# GD32E25x register map
File version: 1.0
GD32E25x ARM 32-bit Cortex-M23 Microcontroller based device
CPU: CM23 r1p0, little endian, no MPU, no FPU, 2 interrupt priority bits
Registers are 32-bit, read-write, reset 0x0 unless marked. A register's access mark holds for its fields unless they carry their own. Offsets are from the block's base; lines under a group give offsets from that group; [hi:lo] are bit positions; {n}, {i} and the like mark numbered series; 'fields as' and 'values as' point back to an identical list; <NAME> marks a mode.

## Memory map
0x40000000 TIMER1 size 0x400 — General-level0-timer
0x40000400 TIMER2 size 0x400 — General-purpose-timers
0x40001000 TIMER5 size 0x400 — Basic-timers
0x40001400 TIMER6 size 0x400 — Basic-timers
0x40002000 TIMER13 size 0x400 — General-purpose-timers
0x40002800 RTC size 0x400 — Real-time clock
0x40002C00 WWDGT size 0x400 — Window watchdog timer
0x40003000 FWDGT size 0x400 — free watchdog timer
0x40003800 SPI1 size 0x400 — Serial Peripheral Interface 1
0x40004400 USART1 size 0x400
0x40005400 I2C0 size 0x400 — Inter integrated circuit
0x40005800 I2C1 size 0x400
0x40007000 PMU size 0x400 — Power management unit
0x40007400 DAC0 size 0x400 — Digital-to-analog converter
0x4000C000 I2C2 size 0x400 — Inter integrated circuit
0x4000CC00 DAC1 size 0x400
0x40010000 SYSCFG size 0x400 — System configuration controller
0x4001001C CMP size 0x80 — Comparator
0x40010400 EXTI size 0x400 — External interrupt/event controller
0x40012400 ADC size 0x400 — Analog to digital converter
0x40012C00 TIMER0 size 0x400 — Advanced-timers
0x40013000 SPI0 size 0x400 — Serial peripheral interface
0x40013800 USART0 size 0x400 — Universal synchronous asynchronous receiver transmitter
0x40014000 TIMER14 size 0x400 — General-purpose-timers
0x40014400 TIMER15 size 0x400 — General-purpose-timers
0x40014800 TIMER16 size 0x400
0x40015800 DBG size 0x400 — Debug
0x40020000 DMA size 0x400 — DMA controller
0x40021000 RCU size 0x400 — Reset and clock unit
0x40022000 FMC size 0x400
0x40023000 CRC size 0x400 — cyclic redundancy check calculation unit
0x40038000 CLA size 0x400 — Configurable Logic Array unit
0x48000000 GPIOA size 0x400 — General-purpose I/Os
0x48000400 GPIOB size 0x400 — General-purpose I/Os
0x48001000 GPIOSP size 0x400 — General-purpose I/Os
0x48001400 GPIOF size 0x400 — General-purpose I/Os
0xE000E100 NVIC size 0x380 — Nested Vectored Interrupt Controller

## Interrupts
0 WWDGT
1 LVD (EXTI)
2 RTC
3 FMC
4 RCU
5 EXTI0_1 (EXTI)
6 EXTI2_3 (EXTI)
7 EXTI4_15 (EXTI)
9 DMA_Channel0 (DMA)
10 DMA_Channel1_2 (DMA)
11 DMA_Channel3_4 (DMA)
12 ADC_CMP (ADC)
13 TIMER0_BRK_UP_TRG_COM (TIMER0)
14 TIMER0_CC (TIMER0)
15 TIMER1
16 TIMER2
17 TIMER5_DAC (TIMER5)
18 TIMER6
19 TIMER13
20 TIMER14
21 TIMER15
22 TIMER16
23 I2C0_EV (I2C0)
24 I2C1_EV (I2C1)
25 SPI0
26 SPI1
27 USART0
28 USART1
32 I2C0_ER (I2C0)
34 I2C1_ER (I2C1)
48 DMA_Channel5_6 (DMA)
82 I2C2_EV (I2C2)
83 I2C2_ER (I2C2)
85 I2C2_WKUP (I2C2)

## CLA — Configurable Logic Array unit
Base 0x40038000
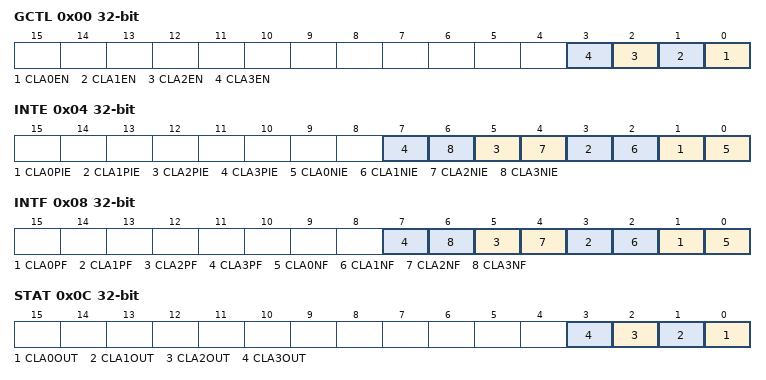
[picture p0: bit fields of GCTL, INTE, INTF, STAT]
0x00 GCTL — Global control register
  [n] CLA{n}EN (n=0..3) — CLA{n} uint enable
0x04 INTE — Interrupt flag enable register
  [2n+1] CLA{n}PIE (n=0..3) — CLA{n} unit posedge interrupt enable
  [2n] CLA{n}NIE (n=0..3) — CLA{n} unit negedge interrupt enable
0x08 INTF — Interrupt flag register
  [2n+1] CLA{n}PF (n=0..3) — CLA{n} unit posegde flag
  [2n] CLA{n}NF (n=0..3) — CLA{n} unit negegde flag
0x0C STAT ro — Status Register
  [n] CLA{n}OUT (n=0..3) — CLA{n} unit output state
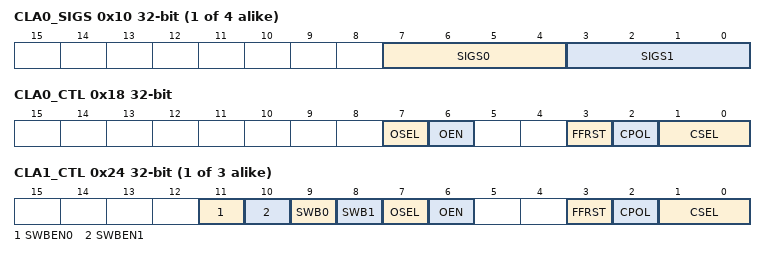
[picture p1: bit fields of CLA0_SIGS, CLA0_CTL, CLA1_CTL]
{0x10+0xC*i} CLA{i}_SIGS (i=0..3) — Signal selection register
  [7:4] SIGS0 — Signal Selector 0 input selection
  [3:0] SIGS1 — Signal Selector 1 input selection
{0x14+0xC*i} CLA{i}_LCUCTL (i=0..3) — LCU control register
  [7:0] LCUCTL
0x18 CLA0_CTL access per field — control register
  [7] OSEL rw — output selection
  [6] OEN rw — output enable
  [3] FFRST wo — Flip-flop output reset
  [2] CPOL rw — Clock polarity
  [1:0] CSEL rw — Clock selection
{0x18+0xC*i} CLA{i}_CTL access per field (i=1..3) — control register
  [11] SWBEN0 rw — Enable software bit 0
  [10] SWBEN1 rw — Enable software bit 1
  [9] SWB0 rw — Software bit 0
  [8] SWB1 rw — Software bit 1
  [7] OSEL rw — output selection
  [6] OEN rw — output enable
  [3] FFRST wo — Flip-flop output reset
  [2] CPOL rw — Clock polarity
  [1:0] CSEL rw — Clock selection
